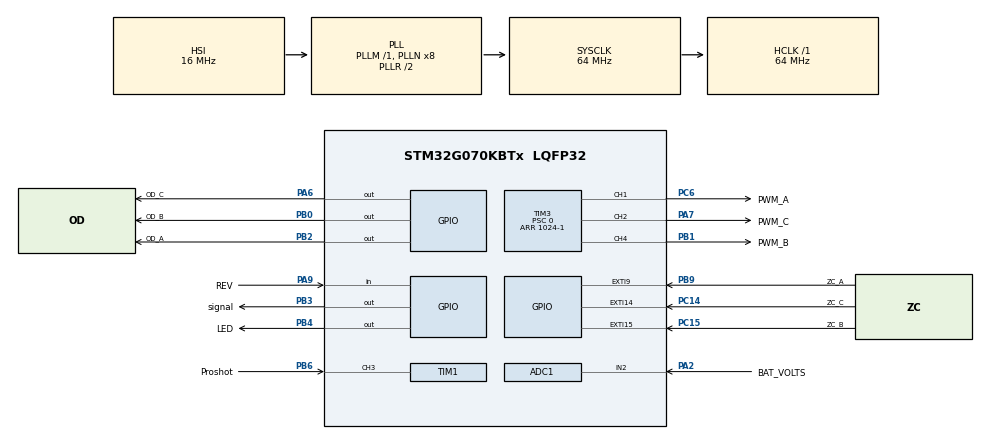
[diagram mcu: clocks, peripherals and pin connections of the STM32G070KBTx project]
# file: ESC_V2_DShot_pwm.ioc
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ADC1.Channel-0\#ChannelRegularConversion=ADC_CHANNEL_2
ADC1.Channel-1\#ChannelRegularConversion=ADC_CHANNEL_TEMPSENSOR
ADC1.ContinuousConvMode=ENABLE
ADC1.DMAContinuousRequests=ENABLE
ADC1.ExternalTrigConv=ADC_SOFTWARE_START
ADC1.ExternalTrigConvEdge=ADC_EXTERNALTRIGCONVEDGE_NONE
ADC1.NbrOfConversion=2
ADC1.NbrOfConversionFlag=1
ADC1.Rank-0\#ChannelRegularConversion=1
ADC1.Rank-1\#ChannelRegularConversion=2
ADC1.SamplingTime-0\#ChannelRegularConversion=ADC_SAMPLINGTIME_COMMON_1
ADC1.SamplingTime-1\#ChannelRegularConversion=ADC_SAMPLINGTIME_COMMON_1
ADC1.SamplingTimeCommon1=ADC_SAMPLETIME_39CYCLES_5
ADC1.SamplingTimeCommon2=ADC_SAMPLETIME_79CYCLES_5
ADC1.SelectedChannel=ADC_CHANNEL_2|ADC_CHANNEL_TEMPSENSOR
ADC1.TriggerFrequencyMode=ADC_TRIGGER_FREQ_LOW
ADC1.master=1
Dma.ADC1.1.Direction=DMA_PERIPH_TO_MEMORY
Dma.ADC1.1.EventEnable=DISABLE
Dma.ADC1.1.Instance=DMA1_Channel5
Dma.ADC1.1.MemDataAlignment=DMA_MDATAALIGN_HALFWORD
Dma.ADC1.1.MemInc=DMA_MINC_ENABLE
Dma.ADC1.1.Mode=DMA_CIRCULAR
Dma.ADC1.1.PeriphDataAlignment=DMA_PDATAALIGN_HALFWORD
Dma.ADC1.1.PeriphInc=DMA_PINC_DISABLE
Dma.ADC1.1.Polarity=HAL_DMAMUX_REQ_GEN_RISING
Dma.ADC1.1.Priority=DMA_PRIORITY_LOW
Dma.ADC1.1.RequestNumber=1
Dma.ADC1.1.SignalID=NONE
Dma.ADC1.1.SyncEnable=DISABLE
Dma.ADC1.1.SyncPolarity=HAL_DMAMUX_SYNC_NO_EVENT
Dma.ADC1.1.SyncRequestNumber=1
Dma.ADC1.1.SyncSignalID=NONE
Dma.MEMTOMEM.2.Direction=DMA_MEMORY_TO_MEMORY
Dma.MEMTOMEM.2.EventEnable=DISABLE
Dma.MEMTOMEM.2.Instance=DMA1_Channel6
Dma.MEMTOMEM.2.MemDataAlignment=DMA_MDATAALIGN_HALFWORD
Dma.MEMTOMEM.2.MemInc=DMA_MINC_ENABLE
Dma.MEMTOMEM.2.Mode=DMA_NORMAL
Dma.MEMTOMEM.2.PeriphDataAlignment=DMA_PDATAALIGN_HALFWORD
Dma.MEMTOMEM.2.PeriphInc=DMA_PINC_ENABLE
Dma.MEMTOMEM.2.Polarity=HAL_DMAMUX_REQ_GEN_RISING
Dma.MEMTOMEM.2.Priority=DMA_PRIORITY_VERY_HIGH
Dma.MEMTOMEM.2.RequestNumber=1
Dma.MEMTOMEM.2.SignalID=NONE
Dma.MEMTOMEM.2.SyncEnable=DISABLE
Dma.MEMTOMEM.2.SyncPolarity=HAL_DMAMUX_SYNC_NO_EVENT
Dma.MEMTOMEM.2.SyncRequestNumber=1
Dma.MEMTOMEM.2.SyncSignalID=NONE
Dma.Request0=TIM1_CH3
Dma.Request1=ADC1
Dma.Request2=MEMTOMEM
Dma.TIM1_CH3.0.Direction=DMA_PERIPH_TO_MEMORY
Dma.TIM1_CH3.0.EventEnable=DISABLE
Dma.TIM1_CH3.0.Instance=DMA1_Channel1
Dma.TIM1_CH3.0.MemDataAlignment=DMA_MDATAALIGN_HALFWORD
Dma.TIM1_CH3.0.MemInc=DMA_MINC_ENABLE
Dma.TIM1_CH3.0.Mode=DMA_CIRCULAR
Dma.TIM1_CH3.0.PeriphDataAlignment=DMA_PDATAALIGN_HALFWORD
Dma.TIM1_CH3.0.PeriphInc=DMA_PINC_DISABLE
Dma.TIM1_CH3.0.Polarity=HAL_DMAMUX_REQ_GEN_RISING
Dma.TIM1_CH3.0.Priority=DMA_PRIORITY_VERY_HIGH
Dma.TIM1_CH3.0.RequestNumber=1
Dma.TIM1_CH3.0.SignalID=NONE
Dma.TIM1_CH3.0.SyncEnable=DISABLE
Dma.TIM1_CH3.0.SyncPolarity=HAL_DMAMUX_SYNC_NO_EVENT
Dma.TIM1_CH3.0.SyncRequestNumber=1
Dma.TIM1_CH3.0.SyncSignalID=NONE
Mcu.Family=STM32G0
Mcu.Name=STM32G070KBTx
Mcu.Package=LQFP32
NVIC.ADC1_IRQn=true\:0\:0\:false\:false\:true\:true\:true\:true
NVIC.DMA1_Channel1_IRQn=true\:0\:0\:true\:false\:true\:true\:true\:true
NVIC.EXTI4_15_IRQn=true\:3\:0\:true\:false\:true\:true\:true\:true
NVIC.TIM15_IRQn=true\:0\:0\:false\:false\:true\:true\:true\:true
NVIC.TIM17_IRQn=true\:0\:0\:true\:false\:true\:true\:true\:true
NVIC.TIM1_CC_IRQn=true\:0\:0\:false\:false\:true\:true\:true\:true
PA13.Mode=Serial_Wire
PA13.Signal=SYS_SWDIO
PA14-BOOT0.Mode=Serial_Wire
PA14-BOOT0.Signal=SYS_SWCLK
PA2.GPIO_Label=BAT_VOLTS
PA2.Mode=IN2
PA2.Signal=ADC1_IN2
PA6.GPIO_Label=OD_C
PA6.GPIO_PuPd=GPIO_PULLDOWN
PA6.GPIO_Speed=GPIO_SPEED_FREQ_MEDIUM
PA6.Signal=GPIO_Output
PA7.GPIO_Label=PWM_C
PA7.GPIO_PuPd=GPIO_PULLDOWN
PA7.Signal=S_TIM3_CH2
PA9.GPIO_Label=REV
PA9.GPIO_PuPd=GPIO_PULLUP
PA9.Signal=GPIO_Input
PB0.GPIO_Label=OD_B
PB0.GPIO_PuPd=GPIO_PULLDOWN
PB0.GPIO_Speed=GPIO_SPEED_FREQ_MEDIUM
PB0.Signal=GPIO_Output
PB1.GPIO_Label=PWM_B
PB1.GPIO_PuPd=GPIO_PULLDOWN
PB1.Signal=S_TIM3_CH4
PB2.GPIO_Label=OD_A
PB2.GPIO_PuPd=GPIO_PULLDOWN
PB2.GPIO_Speed=GPIO_SPEED_FREQ_MEDIUM
PB2.Signal=GPIO_Output
PB3.GPIO_Label=signal
PB3.GPIO_Speed=GPIO_SPEED_FREQ_VERY_HIGH
PB3.Signal=GPIO_Output
PB4.GPIO_Label=LED
PB4.GPIO_Speed=GPIO_SPEED_FREQ_MEDIUM
PB4.Signal=GPIO_Output
PB6.GPIO_FM6=SYSCFG_FASTMODEPLUS_PB6
PB6.GPIO_Label=Proshot
PB6.GPIO_PuPd=GPIO_NOPULL
PB6.GPIO_Speed=GPIO_SPEED_FREQ_VERY_HIGH
PB6.Signal=S_TIM1_CH3
PB9.GPIO_Label=ZC_A
PB9.GPIO_ModeDefaultEXTI=GPIO_MODE_IT_FALLING
PB9.GPIO_PuPd=GPIO_PULLUP
PB9.Signal=GPXTI9
PC14-OSC32_IN\ (PC14).GPIO_Label=ZC_C
PC14-OSC32_IN\ (PC14).GPIO_ModeDefaultEXTI=GPIO_MODE_IT_FALLING
PC14-OSC32_IN\ (PC14).GPIO_PuPd=GPIO_PULLUP
PC14-OSC32_IN\ (PC14).Signal=GPXTI14
PC15-OSC32_OUT\ (PC15).GPIO_Label=ZC_B
PC15-OSC32_OUT\ (PC15).GPIO_ModeDefaultEXTI=GPIO_MODE_IT_FALLING
PC15-OSC32_OUT\ (PC15).GPIO_PuPd=GPIO_PULLUP
PC15-OSC32_OUT\ (PC15).Signal=GPXTI15
PC6.GPIO_Label=PWM_A
PC6.GPIO_PuPd=GPIO_PULLDOWN
PC6.Signal=S_TIM3_CH1
ProjectManager.HeapSize=0x200
ProjectManager.StackSize=0x400
ProjectManager.TargetToolchain=STM32CubeIDE
RCC.ADCFreq_Value=64000000
RCC.AHBFreq_Value=64000000
RCC.CortexFreq_Value=64000000
RCC.EXTERNAL_CLOCK_VALUE=48000
RCC.HCLKFreq_Value=64000000
RCC.HSE_VALUE=8000000
RCC.HSI_VALUE=16000000
RCC.LSE_VALUE=32768
RCC.SYSCLKFreq_VALUE=64000000
RCC.SYSCLKSource=RCC_SYSCLKSOURCE_PLLCLK
RCC.VCOOutputFreq_Value=128000000
SH.S_TIM1_CH3.0=TIM1_CH3,Input_Capture3_from_TI3
SH.S_TIM3_CH1.0=TIM3_CH1,PWM Generation1 CH1
SH.S_TIM3_CH2.0=TIM3_CH2,PWM Generation2 CH2
SH.S_TIM3_CH4.0=TIM3_CH4,PWM Generation4 CH4
TIM1.AutoReloadPreload=TIM_AUTORELOAD_PRELOAD_DISABLE
TIM1.Channel-Input_Capture3_from_TI3=TIM_CHANNEL_3
TIM1.Channel-Input_Capture4_from_TI3_63=TIM_CHANNEL_4
TIM1.Channel-Output\ Compare1\ No\ Output=TIM_CHANNEL_1
TIM1.ICFilter_CH3=0
TIM1.ICPolarity_CH3=TIM_INPUTCHANNELPOLARITY_BOTHEDGE
TIM1.ICPolarity_CH4=TIM_INPUTCHANNELPOLARITY_RISING
TIM1.ICPrescaler-Input_Capture3_from_TI3=TIM_ICPSC_DIV1
TIM1.Prescaler=1
TIM14.Prescaler=64-1
TIM15.Channel-Output\ Compare1\ No\ Output=TIM_CHANNEL_1
TIM15.Period=500
TIM15.Prescaler=64000
TIM15.Pulse-Output\ Compare1\ No\ Output=500
TIM16.Prescaler=64000
TIM17.AutoReloadPreload=TIM_AUTORELOAD_PRELOAD_DISABLE
TIM17.Channel=TIM_CHANNEL_1
TIM17.Period=200
TIM17.Prescaler=64000
TIM3.AutoReloadPreload=TIM_AUTORELOAD_PRELOAD_DISABLE
TIM3.Channel-PWM\ Generation1\ CH1=TIM_CHANNEL_1
TIM3.Channel-PWM\ Generation2\ CH2=TIM_CHANNEL_2
TIM3.Channel-PWM\ Generation4\ CH4=TIM_CHANNEL_4
TIM3.CounterMode=TIM_COUNTERMODE_UP
TIM3.OC1Preload_PWM=DISABLE
TIM3.OC2Preload_PWM=DISABLE
TIM3.OC4Preload_PWM=DISABLE
TIM3.Period=1024-1
TIM3.Prescaler=0
TIM3.TIM_MasterOutputTrigger=TIM_TRGO_UPDATE
TIM6.Prescaler=64-1
TIM7.Prescaler=0
VP_ADC1_TempSens_Input.Mode=IN-TempSens
VP_SYS_VS_DBSignals.Mode=DisableDeadBatterySignals
VP_TIM14_VS_ClockSourceINT.Mode=Enable_Timer
VP_TIM15_VS_no_output1.Mode=Output Compare1 No Output
VP_TIM16_VS_ClockSourceINT.Mode=Enable_Timer
VP_TIM17_VS_ClockSourceINT.Mode=Enable_Timer
VP_TIM17_VS_no_output1.Mode=Output Compare1 No Output
VP_TIM1_VS_indirect_ch3.Mode=Input_Capture4_from_TI3_63
VP_TIM1_VS_no_output1.Mode=Output Compare1 No Output
VP_TIM6_VS_ClockSourceINT.Mode=Enable_Timer
VP_TIM7_VS_ClockSourceINT.Mode=Enable_Timer
board=custom

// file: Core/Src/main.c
/* USER CODE BEGIN Header */
/**
  ******************************************************************************
  * @file           : main.c
  * @brief          : Main program body
  ******************************************************************************
  * @attention
  *
  * Copyright (c) 2022 STMicroelectronics.
  * All rights reserved.
  *
  * This software is licensed under terms that can be found in the LICENSE file
  * in the root directory of this software component.
  * If no LICENSE file comes with this software, it is provided AS-IS.
  *
  ******************************************************************************
  */
/* USER CODE END Header */
#include "main.h"

ADC_HandleTypeDef hadc1;
DMA_HandleTypeDef hdma_adc1;

TIM_HandleTypeDef htim1;
TIM_HandleTypeDef htim3;
TIM_HandleTypeDef htim6;
TIM_HandleTypeDef htim7;
TIM_HandleTypeDef htim14;
TIM_HandleTypeDef htim15;
TIM_HandleTypeDef htim16;
TIM_HandleTypeDef htim17;
DMA_HandleTypeDef hdma_tim1_ch3;

DMA_HandleTypeDef hdma_memtomem_dma1_channel6;
/* USER CODE BEGIN PV */
volatile uint8_t initComplete = 0;
/* USER CODE END PV */

void SystemClock_Config(void);
static void MX_GPIO_Init(void);
static void MX_DMA_Init(void);
static void MX_TIM1_Init(void);
static void MX_TIM3_Init(void);
static void MX_ADC1_Init(void);
static void MX_TIM7_Init(void);
static void MX_TIM17_Init(void);
static void MX_TIM6_Init(void);
static void MX_TIM14_Init(void);
static void MX_TIM16_Init(void);
static void MX_TIM15_Init(void);

int main(void)
{

  /* MCU Configuration--------------------------------------------------------*/

  /* Reset of all peripherals, Initializes the Flash interface and the Systick. */
  HAL_Init();

  /* Configure the system clock */
  SystemClock_Config();

  /* USER CODE BEGIN SysInit */
//  MX_GPIO_Init();
//  HAL_NVIC_DisableIRQ(EXTI4_15_IRQn);
//  MX_DMA_Init();
//  MX_TIM1_Init();
//  MX_TIM3_Init();
//  MX_ADC1_Init();
//  MX_TIM7_Init();
//  MX_TIM17_Init();
//  MX_TIM6_Init();
////  MX_TIM16_Init();
//  MX_TIM14_Init();
//#ifdef _OVERWRITE_
  /* USER CODE END SysInit */

  /* Initialize all configured peripherals */
  MX_GPIO_Init();
  MX_DMA_Init();
  MX_TIM1_Init();
  MX_TIM3_Init();
  MX_ADC1_Init();
  MX_TIM7_Init();
  MX_TIM17_Init();
  MX_TIM6_Init();
  MX_TIM14_Init();
  MX_TIM16_Init();
  MX_TIM15_Init();
  /* USER CODE BEGIN 2 */
//#endif
  /* USER CODE END 2 */

  /* Infinite loop */
  /* USER CODE BEGIN WHILE */

  maincpp();
  while (1)
  {
	  HAL_GPIO_TogglePin(LED_GPIO_Port, LED_Pin);
	  HAL_Delay(100);

    /* USER CODE END WHILE */

  }
}

void SystemClock_Config(void)
{
  RCC_OscInitTypeDef RCC_OscInitStruct = {0};
  RCC_ClkInitTypeDef RCC_ClkInitStruct = {0};

  /** Configure the main internal regulator output voltage
  */
  HAL_PWREx_ControlVoltageScaling(PWR_REGULATOR_VOLTAGE_SCALE1);

  /** Initializes the RCC Oscillators according to the specified parameters
  * in the RCC_OscInitTypeDef structure.
  */
  RCC_OscInitStruct.OscillatorType = RCC_OSCILLATORTYPE_HSI;
  RCC_OscInitStruct.HSIState = RCC_HSI_ON;
  RCC_OscInitStruct.HSIDiv = RCC_HSI_DIV1;
  RCC_OscInitStruct.HSICalibrationValue = RCC_HSICALIBRATION_DEFAULT;
  RCC_OscInitStruct.PLL.PLLState = RCC_PLL_ON;
  RCC_OscInitStruct.PLL.PLLSource = RCC_PLLSOURCE_HSI;
  RCC_OscInitStruct.PLL.PLLM = RCC_PLLM_DIV1;
  RCC_OscInitStruct.PLL.PLLN = 8;
  RCC_OscInitStruct.PLL.PLLP = RCC_PLLP_DIV2;
  RCC_OscInitStruct.PLL.PLLR = RCC_PLLR_DIV2;
  if (HAL_RCC_OscConfig(&RCC_OscInitStruct) != HAL_OK)
  {
    Error_Handler();
  }

  /** Initializes the CPU, AHB and APB buses clocks
  */
  RCC_ClkInitStruct.ClockType = RCC_CLOCKTYPE_HCLK|RCC_CLOCKTYPE_SYSCLK
                              |RCC_CLOCKTYPE_PCLK1;
  RCC_ClkInitStruct.SYSCLKSource = RCC_SYSCLKSOURCE_PLLCLK;
  RCC_ClkInitStruct.AHBCLKDivider = RCC_SYSCLK_DIV1;
  RCC_ClkInitStruct.APB1CLKDivider = RCC_HCLK_DIV1;

  if (HAL_RCC_ClockConfig(&RCC_ClkInitStruct, FLASH_LATENCY_2) != HAL_OK)
  {
    Error_Handler();
  }
}

static void MX_ADC1_Init(void)
{

  ADC_ChannelConfTypeDef sConfig = {0};

  /** Configure the global features of the ADC (Clock, Resolution, Data Alignment and number of conversion)
  */
  hadc1.Instance = ADC1;
  hadc1.Init.ClockPrescaler = ADC_CLOCK_SYNC_PCLK_DIV2;
  hadc1.Init.Resolution = ADC_RESOLUTION_12B;
  hadc1.Init.DataAlign = ADC_DATAALIGN_RIGHT;
  hadc1.Init.ScanConvMode = ADC_SCAN_ENABLE;
  hadc1.Init.EOCSelection = ADC_EOC_SINGLE_CONV;
  hadc1.Init.LowPowerAutoWait = DISABLE;
  hadc1.Init.LowPowerAutoPowerOff = DISABLE;
  hadc1.Init.ContinuousConvMode = ENABLE;
  hadc1.Init.NbrOfConversion = 2;
  hadc1.Init.ExternalTrigConv = ADC_SOFTWARE_START;
  hadc1.Init.ExternalTrigConvEdge = ADC_EXTERNALTRIGCONVEDGE_NONE;
  hadc1.Init.DMAContinuousRequests = ENABLE;
  hadc1.Init.Overrun = ADC_OVR_DATA_PRESERVED;
  hadc1.Init.SamplingTimeCommon1 = ADC_SAMPLETIME_39CYCLES_5;
  hadc1.Init.SamplingTimeCommon2 = ADC_SAMPLETIME_79CYCLES_5;
  hadc1.Init.OversamplingMode = DISABLE;
  hadc1.Init.TriggerFrequencyMode = ADC_TRIGGER_FREQ_LOW;
  if (HAL_ADC_Init(&hadc1) != HAL_OK)
  {
    Error_Handler();
  }

  /** Configure Regular Channel
  */
  sConfig.Channel = ADC_CHANNEL_2;
  sConfig.Rank = ADC_REGULAR_RANK_1;
  sConfig.SamplingTime = ADC_SAMPLINGTIME_COMMON_1;
  if (HAL_ADC_ConfigChannel(&hadc1, &sConfig) != HAL_OK)
  {
    Error_Handler();
  }

  /** Configure Regular Channel
  */
  sConfig.Channel = ADC_CHANNEL_TEMPSENSOR;
  sConfig.Rank = ADC_REGULAR_RANK_2;
  if (HAL_ADC_ConfigChannel(&hadc1, &sConfig) != HAL_OK)
  {
    Error_Handler();
  }

}

static void MX_TIM1_Init(void)
{

  TIM_MasterConfigTypeDef sMasterConfig = {0};
  TIM_OC_InitTypeDef sConfigOC = {0};
  TIM_IC_InitTypeDef sConfigIC = {0};
  TIM_BreakDeadTimeConfigTypeDef sBreakDeadTimeConfig = {0};

  htim1.Instance = TIM1;
  htim1.Init.Prescaler = 1;
  htim1.Init.CounterMode = TIM_COUNTERMODE_UP;
  htim1.Init.Period = 65535;
  htim1.Init.ClockDivision = TIM_CLOCKDIVISION_DIV1;
  htim1.Init.RepetitionCounter = 0;
  htim1.Init.AutoReloadPreload = TIM_AUTORELOAD_PRELOAD_DISABLE;
  if (HAL_TIM_OC_Init(&htim1) != HAL_OK)
  {
    Error_Handler();
  }
  if (HAL_TIM_IC_Init(&htim1) != HAL_OK)
  {
    Error_Handler();
  }
  sMasterConfig.MasterOutputTrigger = TIM_TRGO_RESET;
  sMasterConfig.MasterOutputTrigger2 = TIM_TRGO2_RESET;
  sMasterConfig.MasterSlaveMode = TIM_MASTERSLAVEMODE_DISABLE;
  if (HAL_TIMEx_MasterConfigSynchronization(&htim1, &sMasterConfig) != HAL_OK)
  {
    Error_Handler();
  }
  sConfigOC.OCMode = TIM_OCMODE_TIMING;
  sConfigOC.Pulse = 0;
  sConfigOC.OCPolarity = TIM_OCPOLARITY_HIGH;
  sConfigOC.OCNPolarity = TIM_OCNPOLARITY_HIGH;
  sConfigOC.OCFastMode = TIM_OCFAST_DISABLE;
  sConfigOC.OCIdleState = TIM_OCIDLESTATE_RESET;
  sConfigOC.OCNIdleState = TIM_OCNIDLESTATE_RESET;
  if (HAL_TIM_OC_ConfigChannel(&htim1, &sConfigOC, TIM_CHANNEL_1) != HAL_OK)
  {
    Error_Handler();
  }
  sConfigIC.ICPolarity = TIM_INPUTCHANNELPOLARITY_BOTHEDGE;
  sConfigIC.ICSelection = TIM_ICSELECTION_DIRECTTI;
  sConfigIC.ICPrescaler = TIM_ICPSC_DIV1;
  sConfigIC.ICFilter = 0;
  if (HAL_TIM_IC_ConfigChannel(&htim1, &sConfigIC, TIM_CHANNEL_3) != HAL_OK)
  {
    Error_Handler();
  }
  sConfigIC.ICPolarity = TIM_INPUTCHANNELPOLARITY_RISING;
  sConfigIC.ICSelection = TIM_ICSELECTION_INDIRECTTI;
  if (HAL_TIM_IC_ConfigChannel(&htim1, &sConfigIC, TIM_CHANNEL_4) != HAL_OK)
  {
    Error_Handler();
  }
  sBreakDeadTimeConfig.OffStateRunMode = TIM_OSSR_DISABLE;
  sBreakDeadTimeConfig.OffStateIDLEMode = TIM_OSSI_DISABLE;
  sBreakDeadTimeConfig.LockLevel = TIM_LOCKLEVEL_OFF;
  sBreakDeadTimeConfig.DeadTime = 0;
  sBreakDeadTimeConfig.BreakState = TIM_BREAK_DISABLE;
  sBreakDeadTimeConfig.BreakPolarity = TIM_BREAKPOLARITY_HIGH;
  sBreakDeadTimeConfig.BreakFilter = 0;
  sBreakDeadTimeConfig.BreakAFMode = TIM_BREAK_AFMODE_INPUT;
  sBreakDeadTimeConfig.Break2State = TIM_BREAK2_DISABLE;
  sBreakDeadTimeConfig.Break2Polarity = TIM_BREAK2POLARITY_HIGH;
  sBreakDeadTimeConfig.Break2Filter = 0;
  sBreakDeadTimeConfig.Break2AFMode = TIM_BREAK_AFMODE_INPUT;
  sBreakDeadTimeConfig.AutomaticOutput = TIM_AUTOMATICOUTPUT_DISABLE;
  if (HAL_TIMEx_ConfigBreakDeadTime(&htim1, &sBreakDeadTimeConfig) != HAL_OK)
  {
    Error_Handler();
  }

}

static void MX_TIM3_Init(void)
{

  TIM_MasterConfigTypeDef sMasterConfig = {0};
  TIM_OC_InitTypeDef sConfigOC = {0};

  htim3.Instance = TIM3;
  htim3.Init.Prescaler = 0;
  htim3.Init.CounterMode = TIM_COUNTERMODE_UP;
  htim3.Init.Period = 1024-1;
  htim3.Init.ClockDivision = TIM_CLOCKDIVISION_DIV1;
  htim3.Init.AutoReloadPreload = TIM_AUTORELOAD_PRELOAD_DISABLE;
  if (HAL_TIM_PWM_Init(&htim3) != HAL_OK)
  {
    Error_Handler();
  }
  sMasterConfig.MasterOutputTrigger = TIM_TRGO_UPDATE;
  sMasterConfig.MasterSlaveMode = TIM_MASTERSLAVEMODE_DISABLE;
  if (HAL_TIMEx_MasterConfigSynchronization(&htim3, &sMasterConfig) != HAL_OK)
  {
    Error_Handler();
  }
  sConfigOC.OCMode = TIM_OCMODE_PWM1;
  sConfigOC.Pulse = 0;
  sConfigOC.OCPolarity = TIM_OCPOLARITY_HIGH;
  sConfigOC.OCFastMode = TIM_OCFAST_DISABLE;
  if (HAL_TIM_PWM_ConfigChannel(&htim3, &sConfigOC, TIM_CHANNEL_1) != HAL_OK)
  {
    Error_Handler();
  }
  __HAL_TIM_DISABLE_OCxPRELOAD(&htim3, TIM_CHANNEL_1);
  if (HAL_TIM_PWM_ConfigChannel(&htim3, &sConfigOC, TIM_CHANNEL_2) != HAL_OK)
  {
    Error_Handler();
  }
  __HAL_TIM_DISABLE_OCxPRELOAD(&htim3, TIM_CHANNEL_2);
  if (HAL_TIM_PWM_ConfigChannel(&htim3, &sConfigOC, TIM_CHANNEL_4) != HAL_OK)
  {
    Error_Handler();
  }
  __HAL_TIM_DISABLE_OCxPRELOAD(&htim3, TIM_CHANNEL_4);
  HAL_TIM_MspPostInit(&htim3);

}

static void MX_TIM6_Init(void)
{

  TIM_MasterConfigTypeDef sMasterConfig = {0};

  htim6.Instance = TIM6;
  htim6.Init.Prescaler = 64-1;
  htim6.Init.CounterMode = TIM_COUNTERMODE_UP;
  htim6.Init.Period = 65535;
  htim6.Init.AutoReloadPreload = TIM_AUTORELOAD_PRELOAD_DISABLE;
  if (HAL_TIM_Base_Init(&htim6) != HAL_OK)
  {
    Error_Handler();
  }
  sMasterConfig.MasterOutputTrigger = TIM_TRGO_RESET;
  sMasterConfig.MasterSlaveMode = TIM_MASTERSLAVEMODE_DISABLE;
  if (HAL_TIMEx_MasterConfigSynchronization(&htim6, &sMasterConfig) != HAL_OK)
  {
    Error_Handler();
  }

}

static void MX_TIM7_Init(void)
{

  TIM_MasterConfigTypeDef sMasterConfig = {0};

  htim7.Instance = TIM7;
  htim7.Init.Prescaler = 0;
  htim7.Init.CounterMode = TIM_COUNTERMODE_UP;
  htim7.Init.Period = 65535;
  htim7.Init.AutoReloadPreload = TIM_AUTORELOAD_PRELOAD_DISABLE;
  if (HAL_TIM_Base_Init(&htim7) != HAL_OK)
  {
    Error_Handler();
  }
  sMasterConfig.MasterOutputTrigger = TIM_TRGO_RESET;
  sMasterConfig.MasterSlaveMode = TIM_MASTERSLAVEMODE_DISABLE;
  if (HAL_TIMEx_MasterConfigSynchronization(&htim7, &sMasterConfig) != HAL_OK)
  {
    Error_Handler();
  }

}

static void MX_TIM14_Init(void)
{

  htim14.Instance = TIM14;
  htim14.Init.Prescaler = 64-1;
  htim14.Init.CounterMode = TIM_COUNTERMODE_UP;
  htim14.Init.Period = 65535;
  htim14.Init.ClockDivision = TIM_CLOCKDIVISION_DIV1;
  htim14.Init.AutoReloadPreload = TIM_AUTORELOAD_PRELOAD_DISABLE;
  if (HAL_TIM_Base_Init(&htim14) != HAL_OK)
  {
    Error_Handler();
  }

}

static void MX_TIM15_Init(void)
{

  TIM_MasterConfigTypeDef sMasterConfig = {0};
  TIM_OC_InitTypeDef sConfigOC = {0};
  TIM_BreakDeadTimeConfigTypeDef sBreakDeadTimeConfig = {0};

  htim15.Instance = TIM15;
  htim15.Init.Prescaler = 64000;
  htim15.Init.CounterMode = TIM_COUNTERMODE_UP;
  htim15.Init.Period = 500;
  htim15.Init.ClockDivision = TIM_CLOCKDIVISION_DIV1;
  htim15.Init.RepetitionCounter = 0;
  htim15.Init.AutoReloadPreload = TIM_AUTORELOAD_PRELOAD_DISABLE;
  if (HAL_TIM_OC_Init(&htim15) != HAL_OK)
  {
    Error_Handler();
  }
  sMasterConfig.MasterOutputTrigger = TIM_TRGO_RESET;
  sMasterConfig.MasterSlaveMode = TIM_MASTERSLAVEMODE_DISABLE;
  if (HAL_TIMEx_MasterConfigSynchronization(&htim15, &sMasterConfig) != HAL_OK)
  {
    Error_Handler();
  }
  sConfigOC.OCMode = TIM_OCMODE_TIMING;
  sConfigOC.Pulse = 500;
  sConfigOC.OCPolarity = TIM_OCPOLARITY_HIGH;
  sConfigOC.OCNPolarity = TIM_OCNPOLARITY_HIGH;
  sConfigOC.OCFastMode = TIM_OCFAST_DISABLE;
  sConfigOC.OCIdleState = TIM_OCIDLESTATE_RESET;
  sConfigOC.OCNIdleState = TIM_OCNIDLESTATE_RESET;
  if (HAL_TIM_OC_ConfigChannel(&htim15, &sConfigOC, TIM_CHANNEL_1) != HAL_OK)
  {
    Error_Handler();
  }
  sBreakDeadTimeConfig.OffStateRunMode = TIM_OSSR_DISABLE;
  sBreakDeadTimeConfig.OffStateIDLEMode = TIM_OSSI_DISABLE;
  sBreakDeadTimeConfig.LockLevel = TIM_LOCKLEVEL_OFF;
  sBreakDeadTimeConfig.DeadTime = 0;
  sBreakDeadTimeConfig.BreakState = TIM_BREAK_DISABLE;
  sBreakDeadTimeConfig.BreakPolarity = TIM_BREAKPOLARITY_HIGH;
  sBreakDeadTimeConfig.BreakFilter = 0;
  sBreakDeadTimeConfig.AutomaticOutput = TIM_AUTOMATICOUTPUT_DISABLE;
  if (HAL_TIMEx_ConfigBreakDeadTime(&htim15, &sBreakDeadTimeConfig) != HAL_OK)
  {
    Error_Handler();
  }

}

static void MX_TIM16_Init(void)
{

  htim16.Instance = TIM16;
  htim16.Init.Prescaler = 64000;
  htim16.Init.CounterMode = TIM_COUNTERMODE_UP;
  htim16.Init.Period = 65535;
  htim16.Init.ClockDivision = TIM_CLOCKDIVISION_DIV1;
  htim16.Init.RepetitionCounter = 0;
  htim16.Init.AutoReloadPreload = TIM_AUTORELOAD_PRELOAD_DISABLE;
  if (HAL_TIM_Base_Init(&htim16) != HAL_OK)
  {
    Error_Handler();
  }

}

static void MX_TIM17_Init(void)
{

  TIM_OC_InitTypeDef sConfigOC = {0};
  TIM_BreakDeadTimeConfigTypeDef sBreakDeadTimeConfig = {0};

  htim17.Instance = TIM17;
  htim17.Init.Prescaler = 64000;
  htim17.Init.CounterMode = TIM_COUNTERMODE_UP;
  htim17.Init.Period = 200;
  htim17.Init.ClockDivision = TIM_CLOCKDIVISION_DIV1;
  htim17.Init.RepetitionCounter = 0;
  htim17.Init.AutoReloadPreload = TIM_AUTORELOAD_PRELOAD_DISABLE;
  if (HAL_TIM_Base_Init(&htim17) != HAL_OK)
  {
    Error_Handler();
  }
  if (HAL_TIM_OC_Init(&htim17) != HAL_OK)
  {
    Error_Handler();
  }
  sConfigOC.OCMode = TIM_OCMODE_TIMING;
  sConfigOC.Pulse = 0;
  sConfigOC.OCPolarity = TIM_OCPOLARITY_HIGH;
  sConfigOC.OCNPolarity = TIM_OCNPOLARITY_HIGH;
  sConfigOC.OCFastMode = TIM_OCFAST_DISABLE;
  sConfigOC.OCIdleState = TIM_OCIDLESTATE_RESET;
  sConfigOC.OCNIdleState = TIM_OCNIDLESTATE_RESET;
  if (HAL_TIM_OC_ConfigChannel(&htim17, &sConfigOC, TIM_CHANNEL_1) != HAL_OK)
  {
    Error_Handler();
  }
  sBreakDeadTimeConfig.OffStateRunMode = TIM_OSSR_DISABLE;
  sBreakDeadTimeConfig.OffStateIDLEMode = TIM_OSSI_DISABLE;
  sBreakDeadTimeConfig.LockLevel = TIM_LOCKLEVEL_OFF;
  sBreakDeadTimeConfig.DeadTime = 0;
  sBreakDeadTimeConfig.BreakState = TIM_BREAK_DISABLE;
  sBreakDeadTimeConfig.BreakPolarity = TIM_BREAKPOLARITY_HIGH;
  sBreakDeadTimeConfig.BreakFilter = 0;
  sBreakDeadTimeConfig.AutomaticOutput = TIM_AUTOMATICOUTPUT_DISABLE;
  if (HAL_TIMEx_ConfigBreakDeadTime(&htim17, &sBreakDeadTimeConfig) != HAL_OK)
  {
    Error_Handler();
  }

}

static void MX_DMA_Init(void)
{

  /* DMA controller clock enable */
  __HAL_RCC_DMA1_CLK_ENABLE();

  /* Configure DMA request hdma_memtomem_dma1_channel6 on DMA1_Channel6 */
  hdma_memtomem_dma1_channel6.Instance = DMA1_Channel6;
  hdma_memtomem_dma1_channel6.Init.Request = DMA_REQUEST_MEM2MEM;
  hdma_memtomem_dma1_channel6.Init.Direction = DMA_MEMORY_TO_MEMORY;
  hdma_memtomem_dma1_channel6.Init.PeriphInc = DMA_PINC_ENABLE;
  hdma_memtomem_dma1_channel6.Init.MemInc = DMA_MINC_ENABLE;
  hdma_memtomem_dma1_channel6.Init.PeriphDataAlignment = DMA_PDATAALIGN_HALFWORD;
  hdma_memtomem_dma1_channel6.Init.MemDataAlignment = DMA_MDATAALIGN_HALFWORD;
  hdma_memtomem_dma1_channel6.Init.Mode = DMA_NORMAL;
  hdma_memtomem_dma1_channel6.Init.Priority = DMA_PRIORITY_VERY_HIGH;
  if (HAL_DMA_Init(&hdma_memtomem_dma1_channel6) != HAL_OK)
  {
    Error_Handler( );
  }

  /* DMA interrupt init */
  /* DMA1_Channel1_IRQn interrupt configuration */
  HAL_NVIC_SetPriority(DMA1_Channel1_IRQn, 0, 0);
  HAL_NVIC_EnableIRQ(DMA1_Channel1_IRQn);

}

static void MX_GPIO_Init(void)
{
  GPIO_InitTypeDef GPIO_InitStruct = {0};

  /* GPIO Ports Clock Enable */
  __HAL_RCC_GPIOB_CLK_ENABLE();
  __HAL_RCC_GPIOC_CLK_ENABLE();
  __HAL_RCC_GPIOA_CLK_ENABLE();

  /*Configure GPIO pin Output Level */
  HAL_GPIO_WritePin(OD_C_GPIO_Port, OD_C_Pin, GPIO_PIN_RESET);

  /*Configure GPIO pin Output Level */
  HAL_GPIO_WritePin(GPIOB, OD_B_Pin|OD_A_Pin|signal_Pin|LED_Pin, GPIO_PIN_RESET);

  /*Configure GPIO pin : ZC_A_Pin */
  GPIO_InitStruct.Pin = ZC_A_Pin;
  GPIO_InitStruct.Mode = GPIO_MODE_IT_FALLING;
  GPIO_InitStruct.Pull = GPIO_PULLUP;
  HAL_GPIO_Init(ZC_A_GPIO_Port, &GPIO_InitStruct);

  /*Configure GPIO pins : ZC_C_Pin ZC_B_Pin */
  GPIO_InitStruct.Pin = ZC_C_Pin|ZC_B_Pin;
  GPIO_InitStruct.Mode = GPIO_MODE_IT_FALLING;
  GPIO_InitStruct.Pull = GPIO_PULLUP;
  HAL_GPIO_Init(GPIOC, &GPIO_InitStruct);

  /*Configure GPIO pin : OD_C_Pin */
  GPIO_InitStruct.Pin = OD_C_Pin;
  GPIO_InitStruct.Mode = GPIO_MODE_OUTPUT_PP;
  GPIO_InitStruct.Pull = GPIO_PULLDOWN;
  GPIO_InitStruct.Speed = GPIO_SPEED_FREQ_MEDIUM;
  HAL_GPIO_Init(OD_C_GPIO_Port, &GPIO_InitStruct);

  /*Configure GPIO pins : OD_B_Pin OD_A_Pin */
  GPIO_InitStruct.Pin = OD_B_Pin|OD_A_Pin;
  GPIO_InitStruct.Mode = GPIO_MODE_OUTPUT_PP;
  GPIO_InitStruct.Pull = GPIO_PULLDOWN;
  GPIO_InitStruct.Speed = GPIO_SPEED_FREQ_MEDIUM;
  HAL_GPIO_Init(GPIOB, &GPIO_InitStruct);

  /*Configure GPIO pin : REV_Pin */
  GPIO_InitStruct.Pin = REV_Pin;
  GPIO_InitStruct.Mode = GPIO_MODE_INPUT;
  GPIO_InitStruct.Pull = GPIO_PULLUP;
  HAL_GPIO_Init(REV_GPIO_Port, &GPIO_InitStruct);

  /*Configure GPIO pin : signal_Pin */
  GPIO_InitStruct.Pin = signal_Pin;
  GPIO_InitStruct.Mode = GPIO_MODE_OUTPUT_PP;
  GPIO_InitStruct.Pull = GPIO_NOPULL;
  GPIO_InitStruct.Speed = GPIO_SPEED_FREQ_VERY_HIGH;
  HAL_GPIO_Init(signal_GPIO_Port, &GPIO_InitStruct);

  /*Configure GPIO pin : LED_Pin */
  GPIO_InitStruct.Pin = LED_Pin;
  GPIO_InitStruct.Mode = GPIO_MODE_OUTPUT_PP;
  GPIO_InitStruct.Pull = GPIO_NOPULL;
  GPIO_InitStruct.Speed = GPIO_SPEED_FREQ_MEDIUM;
  HAL_GPIO_Init(LED_GPIO_Port, &GPIO_InitStruct);

  /* EXTI interrupt init*/
  HAL_NVIC_SetPriority(EXTI4_15_IRQn, 3, 0);
  HAL_NVIC_EnableIRQ(EXTI4_15_IRQn);

}

void Error_Handler(void)
{
  __disable_irq();
  while (1)
  {
  }
}
